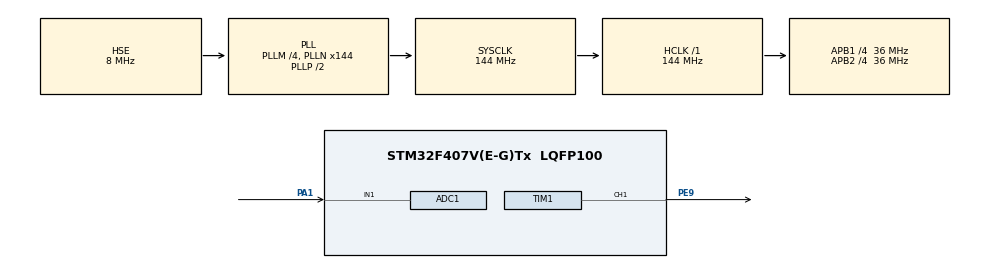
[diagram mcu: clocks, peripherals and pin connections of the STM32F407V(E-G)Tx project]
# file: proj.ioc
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ADC1.Channel-0\#ChannelRegularConversion=ADC_CHANNEL_1
ADC1.ClockPrescaler=ADC_CLOCK_SYNC_PCLK_DIV8
ADC1.ContinuousConvMode=ENABLE
ADC1.DMAContinuousRequests=ENABLE
ADC1.EOCSelection=ADC_EOC_SEQ_CONV
ADC1.NbrOfConversion=1
ADC1.NbrOfConversionFlag=1
ADC1.Rank-0\#ChannelRegularConversion=1
ADC1.SamplingTime-0\#ChannelRegularConversion=ADC_SAMPLETIME_112CYCLES
ADC1.master=1
Dma.ADC1.1.Direction=DMA_PERIPH_TO_MEMORY
Dma.ADC1.1.FIFOMode=DMA_FIFOMODE_DISABLE
Dma.ADC1.1.Instance=DMA2_Stream0
Dma.ADC1.1.MemDataAlignment=DMA_MDATAALIGN_HALFWORD
Dma.ADC1.1.MemInc=DMA_MINC_ENABLE
Dma.ADC1.1.Mode=DMA_NORMAL
Dma.ADC1.1.PeriphDataAlignment=DMA_PDATAALIGN_HALFWORD
Dma.ADC1.1.PeriphInc=DMA_PINC_DISABLE
Dma.ADC1.1.Priority=DMA_PRIORITY_LOW
Dma.Request0=TIM1_CH1
Dma.Request1=ADC1
Dma.TIM1_CH1.0.Direction=DMA_MEMORY_TO_PERIPH
Dma.TIM1_CH1.0.FIFOMode=DMA_FIFOMODE_DISABLE
Dma.TIM1_CH1.0.Instance=DMA2_Stream1
Dma.TIM1_CH1.0.MemDataAlignment=DMA_MDATAALIGN_HALFWORD
Dma.TIM1_CH1.0.MemInc=DMA_MINC_ENABLE
Dma.TIM1_CH1.0.Mode=DMA_NORMAL
Dma.TIM1_CH1.0.PeriphDataAlignment=DMA_PDATAALIGN_HALFWORD
Dma.TIM1_CH1.0.PeriphInc=DMA_PINC_DISABLE
Dma.TIM1_CH1.0.Priority=DMA_PRIORITY_LOW
Mcu.Family=STM32F4
Mcu.Name=STM32F407V(E-G)Tx
Mcu.Package=LQFP100
NVIC.DMA2_Stream0_IRQn=true\:0\:0\:false\:false\:true\:false\:true
NVIC.DMA2_Stream1_IRQn=true\:0\:0\:false\:false\:true\:false\:true
NVIC.PriorityGroup=NVIC_PRIORITYGROUP_4
PA1.Signal=ADCx_IN1
PE9.Signal=S_TIM1_CH1
PH0-OSC_IN.Mode=HSE-External-Oscillator
PH0-OSC_IN.Signal=RCC_OSC_IN
PH1-OSC_OUT.Mode=HSE-External-Oscillator
PH1-OSC_OUT.Signal=RCC_OSC_OUT
ProjectManager.HeapSize=0x200
ProjectManager.StackSize=0x400
ProjectManager.TargetToolchain=STM32CubeIDE
RCC.48MHZClocksFreq_Value=72000000
RCC.AHBFreq_Value=144000000
RCC.APB1CLKDivider=RCC_HCLK_DIV4
RCC.APB1Freq_Value=36000000
RCC.APB1TimFreq_Value=72000000
RCC.APB2CLKDivider=RCC_HCLK_DIV4
RCC.APB2Freq_Value=36000000
RCC.APB2TimFreq_Value=72000000
RCC.CortexFreq_Value=144000000
RCC.HCLKFreq_Value=144000000
RCC.HSE_VALUE=8000000
RCC.HSI_VALUE=16000000
RCC.LSE_VALUE=0
RCC.PLLM=4
RCC.PLLN=144
RCC.PLLSourceVirtual=RCC_PLLSOURCE_HSE
RCC.SYSCLKFreq_VALUE=144000000
RCC.SYSCLKSource=RCC_SYSCLKSOURCE_PLLCLK
RCC.VCOOutputFreq_Value=288000000
SH.ADCx_IN1.0=ADC1_IN1,IN1
SH.S_TIM1_CH1.0=TIM1_CH1,PWM Generation1 CH1
TIM1.Channel-PWM\ Generation1\ CH1=TIM_CHANNEL_1
TIM1.Period=90-1
VP_TIM1_VS_ClockSourceINT.Mode=Internal
board=custom

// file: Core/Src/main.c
/* USER CODE BEGIN Header */
/**
  ******************************************************************************
  * @file           : main.c
  * @brief          : Main program body
  ******************************************************************************
  * @attention
  *
  * <h2><center>&copy; Copyright (c) 2021 STMicroelectronics.
  * All rights reserved.</center></h2>
  *
  * This software component is licensed by ST under BSD 3-Clause license,
  * the "License"; You may not use this file except in compliance with the
  * License. You may obtain a copy of the License at:
  *                        opensource.org/licenses/BSD-3-Clause
  *
  ******************************************************************************
  */
/* USER CODE END Header */
#include "main.h"

ADC_HandleTypeDef hadc1;
DMA_HandleTypeDef hdma_adc1;

TIM_HandleTypeDef htim1;
DMA_HandleTypeDef hdma_tim1_ch1;

/* USER CODE BEGIN PV */
uint8_t flag_adc_dma = 0;
/* USER CODE END PV */

void SystemClock_Config(void);
static void MX_GPIO_Init(void);
static void MX_DMA_Init(void);
static void MX_TIM1_Init(void);
static void MX_ADC1_Init(void);

/* USER CODE BEGIN 0 */
#define MAX_LED 64 // max LEDs that we have in a cascade

uint8_t LED_Data[MAX_LED][4];  // matrix of 4 columns, number of rows = number of LEDs we have

int datasentflag=0;  // to make sure that the dma does not send another data while the first data is still transmitted

void HAL_TIM_PWM_PulseFinishedCallback(TIM_HandleTypeDef *htim)  // this callback is called when data transmission is finished
{
	HAL_TIM_PWM_Stop_DMA(&htim1, TIM_CHANNEL_1);  // stop dma, when the transmission is finished
	datasentflag = 1;
}

void Set_LED (int LEDnum, int Red, int Green, int Blue)
{
	LED_Data[LEDnum][0] = LEDnum;
	LED_Data[LEDnum][1] = Green;  // store green first as ws2821b requires this order (g,r,b)
	LED_Data[LEDnum][2] = Red;
	LED_Data[LEDnum][3] = Blue;
}

uint16_t pwmData[(24*MAX_LED)+50]; // store 24 bits for each led + 50 values for reset code

void WS2812_Send (void)
{
	uint32_t indx=0;
	uint32_t color;  //32 bit variable to store 24 bits of color

	for (int i= 0; i<MAX_LED; i++)  // iterate through all of the LEDs
	{

		color = ((LED_Data[i][1]<<16) | (LED_Data[i][2]<<8) | (LED_Data[i][3])); // green red blue

		for (int i=23; i>=0; i--) // iterate through the 24 bits which specify the color
		{
			if (color&(1<<i))
			{
				pwmData[indx] = 57; // if the bit is 1, the duty cycle is 64%
			}

			else pwmData[indx] = 28;  // if the bit is 0, the duty cycle is 32%

			indx++;
		}

	}

	for (int i=0; i<50; i++)  // store values to keep the pulse low for 50+ us, reset code
	{
		pwmData[indx] = 0;
		indx++;
	}
	HAL_TIM_PWM_Start_DMA(&htim1, TIM_CHANNEL_1, (uint32_t *)pwmData, indx);  // send the data to the dma
	while (!datasentflag){};  // this flag will be set when the data transmission is finished, dma is stopped and now we can send another data
	datasentflag = 0;
}
/* USER CODE END 0 */

int main(void)
{

  /* MCU Configuration--------------------------------------------------------*/

  /* Reset of all peripherals, Initializes the Flash interface and the Systick. */
  HAL_Init();

  /* Configure the system clock */
  SystemClock_Config();

  /* Initialize all configured peripherals */
  MX_GPIO_Init();
  MX_DMA_Init();
  MX_TIM1_Init();
  MX_ADC1_Init();
  /* USER CODE BEGIN 2 */

  uint16_t ADCBuffer[1024];

  HAL_ADC_Start_DMA(&hadc1,(uint16_t *)&ADCBuffer, (1024 * 2));
  if(flag_adc_dma == 1){
	  HAL_ADC_Stop_DMA(&hadc1);
	  flag_adc_dma = 0;
  }

  int lst[64];
    for(int i = 0; i < 64; i++){
        lst[i] = 0;
    }
    //put the first one to the end and increase by a certain number
    int v[8] = {2, 5, 4, 8, 3, 5, 8, 2};
    for(int k=0; k<8; k++){
        int lst_position = k + 64;
        int meaning = v[k];
        int temp = 0;
        while(temp < meaning){
            temp += 1;
            lst_position -= 7;
            lst[lst_position] = 1;
            lst_position--;
        }
    }

        void WS_Reset(void){
        	for (int i=0; i < 64; i++){
            Set_LED(i, 0, 0, 0);
          }
        	WS2812_Send();
        }

        void WS_Set(int matrix[]){
            for (int i=0; i < 64; i++){
              if (matrix[i]==1){
                Set_LED(i, 67, 4, 4);
              }
              else {
                Set_LED(i, 0, 0, 0);
              }
            }
            WS2812_Send();
        }
  /* USER CODE END 2 */

  /* Infinite loop */
  /* USER CODE BEGIN WHILE */
  while (1)
  {
	  WS_Set(lst);
	  HAL_Delay(200);

	  //	 		  	  WS_Reset();
	  //	 		  	  HAL_Delay(200);
    /* USER CODE END WHILE */

  }
}

void SystemClock_Config(void)
{
  RCC_OscInitTypeDef RCC_OscInitStruct = {0};
  RCC_ClkInitTypeDef RCC_ClkInitStruct = {0};

  /** Configure the main internal regulator output voltage
  */
  __HAL_RCC_PWR_CLK_ENABLE();
  __HAL_PWR_VOLTAGESCALING_CONFIG(PWR_REGULATOR_VOLTAGE_SCALE1);
  /** Initializes the RCC Oscillators according to the specified parameters
  * in the RCC_OscInitTypeDef structure.
  */
  RCC_OscInitStruct.OscillatorType = RCC_OSCILLATORTYPE_HSE;
  RCC_OscInitStruct.HSEState = RCC_HSE_ON;
  RCC_OscInitStruct.PLL.PLLState = RCC_PLL_ON;
  RCC_OscInitStruct.PLL.PLLSource = RCC_PLLSOURCE_HSE;
  RCC_OscInitStruct.PLL.PLLM = 4;
  RCC_OscInitStruct.PLL.PLLN = 144;
  RCC_OscInitStruct.PLL.PLLP = RCC_PLLP_DIV2;
  RCC_OscInitStruct.PLL.PLLQ = 4;
  if (HAL_RCC_OscConfig(&RCC_OscInitStruct) != HAL_OK)
  {
    Error_Handler();
  }
  /** Initializes the CPU, AHB and APB buses clocks
  */
  RCC_ClkInitStruct.ClockType = RCC_CLOCKTYPE_HCLK|RCC_CLOCKTYPE_SYSCLK
                              |RCC_CLOCKTYPE_PCLK1|RCC_CLOCKTYPE_PCLK2;
  RCC_ClkInitStruct.SYSCLKSource = RCC_SYSCLKSOURCE_PLLCLK;
  RCC_ClkInitStruct.AHBCLKDivider = RCC_SYSCLK_DIV1;
  RCC_ClkInitStruct.APB1CLKDivider = RCC_HCLK_DIV4;
  RCC_ClkInitStruct.APB2CLKDivider = RCC_HCLK_DIV4;

  if (HAL_RCC_ClockConfig(&RCC_ClkInitStruct, FLASH_LATENCY_4) != HAL_OK)
  {
    Error_Handler();
  }
}

static void MX_ADC1_Init(void)
{

  ADC_ChannelConfTypeDef sConfig = {0};

  /** Configure the global features of the ADC (Clock, Resolution, Data Alignment and number of conversion)
  */
  hadc1.Instance = ADC1;
  hadc1.Init.ClockPrescaler = ADC_CLOCK_SYNC_PCLK_DIV8;
  hadc1.Init.Resolution = ADC_RESOLUTION_12B;
  hadc1.Init.ScanConvMode = DISABLE;
  hadc1.Init.ContinuousConvMode = ENABLE;
  hadc1.Init.DiscontinuousConvMode = DISABLE;
  hadc1.Init.ExternalTrigConvEdge = ADC_EXTERNALTRIGCONVEDGE_NONE;
  hadc1.Init.ExternalTrigConv = ADC_SOFTWARE_START;
  hadc1.Init.DataAlign = ADC_DATAALIGN_RIGHT;
  hadc1.Init.NbrOfConversion = 1;
  hadc1.Init.DMAContinuousRequests = ENABLE;
  hadc1.Init.EOCSelection = ADC_EOC_SEQ_CONV;
  if (HAL_ADC_Init(&hadc1) != HAL_OK)
  {
    Error_Handler();
  }
  /** Configure for the selected ADC regular channel its corresponding rank in the sequencer and its sample time.
  */
  sConfig.Channel = ADC_CHANNEL_1;
  sConfig.Rank = 1;
  sConfig.SamplingTime = ADC_SAMPLETIME_112CYCLES;
  if (HAL_ADC_ConfigChannel(&hadc1, &sConfig) != HAL_OK)
  {
    Error_Handler();
  }

}

static void MX_TIM1_Init(void)
{

  TIM_ClockConfigTypeDef sClockSourceConfig = {0};
  TIM_MasterConfigTypeDef sMasterConfig = {0};
  TIM_OC_InitTypeDef sConfigOC = {0};
  TIM_BreakDeadTimeConfigTypeDef sBreakDeadTimeConfig = {0};

  htim1.Instance = TIM1;
  htim1.Init.Prescaler = 0;
  htim1.Init.CounterMode = TIM_COUNTERMODE_UP;
  htim1.Init.Period = 90-1;
  htim1.Init.ClockDivision = TIM_CLOCKDIVISION_DIV1;
  htim1.Init.RepetitionCounter = 0;
  htim1.Init.AutoReloadPreload = TIM_AUTORELOAD_PRELOAD_DISABLE;
  if (HAL_TIM_Base_Init(&htim1) != HAL_OK)
  {
    Error_Handler();
  }
  sClockSourceConfig.ClockSource = TIM_CLOCKSOURCE_INTERNAL;
  if (HAL_TIM_ConfigClockSource(&htim1, &sClockSourceConfig) != HAL_OK)
  {
    Error_Handler();
  }
  if (HAL_TIM_PWM_Init(&htim1) != HAL_OK)
  {
    Error_Handler();
  }
  sMasterConfig.MasterOutputTrigger = TIM_TRGO_RESET;
  sMasterConfig.MasterSlaveMode = TIM_MASTERSLAVEMODE_DISABLE;
  if (HAL_TIMEx_MasterConfigSynchronization(&htim1, &sMasterConfig) != HAL_OK)
  {
    Error_Handler();
  }
  sConfigOC.OCMode = TIM_OCMODE_PWM1;
  sConfigOC.Pulse = 0;
  sConfigOC.OCPolarity = TIM_OCPOLARITY_HIGH;
  sConfigOC.OCNPolarity = TIM_OCNPOLARITY_HIGH;
  sConfigOC.OCFastMode = TIM_OCFAST_DISABLE;
  sConfigOC.OCIdleState = TIM_OCIDLESTATE_RESET;
  sConfigOC.OCNIdleState = TIM_OCNIDLESTATE_RESET;
  if (HAL_TIM_PWM_ConfigChannel(&htim1, &sConfigOC, TIM_CHANNEL_1) != HAL_OK)
  {
    Error_Handler();
  }
  sBreakDeadTimeConfig.OffStateRunMode = TIM_OSSR_DISABLE;
  sBreakDeadTimeConfig.OffStateIDLEMode = TIM_OSSI_DISABLE;
  sBreakDeadTimeConfig.LockLevel = TIM_LOCKLEVEL_OFF;
  sBreakDeadTimeConfig.DeadTime = 0;
  sBreakDeadTimeConfig.BreakState = TIM_BREAK_DISABLE;
  sBreakDeadTimeConfig.BreakPolarity = TIM_BREAKPOLARITY_HIGH;
  sBreakDeadTimeConfig.AutomaticOutput = TIM_AUTOMATICOUTPUT_DISABLE;
  if (HAL_TIMEx_ConfigBreakDeadTime(&htim1, &sBreakDeadTimeConfig) != HAL_OK)
  {
    Error_Handler();
  }
  HAL_TIM_MspPostInit(&htim1);

}

static void MX_DMA_Init(void)
{

  /* DMA controller clock enable */
  __HAL_RCC_DMA2_CLK_ENABLE();

  /* DMA interrupt init */
  /* DMA2_Stream0_IRQn interrupt configuration */
  HAL_NVIC_SetPriority(DMA2_Stream0_IRQn, 0, 0);
  HAL_NVIC_EnableIRQ(DMA2_Stream0_IRQn);
  /* DMA2_Stream1_IRQn interrupt configuration */
  HAL_NVIC_SetPriority(DMA2_Stream1_IRQn, 0, 0);
  HAL_NVIC_EnableIRQ(DMA2_Stream1_IRQn);

}

static void MX_GPIO_Init(void)
{

  /* GPIO Ports Clock Enable */
  __HAL_RCC_GPIOH_CLK_ENABLE();
  __HAL_RCC_GPIOA_CLK_ENABLE();
  __HAL_RCC_GPIOE_CLK_ENABLE();

}

void Error_Handler(void)
{
  __disable_irq();
  while (1)
  {
  }
}

/************************ (C) COPYRIGHT STMicroelectronics *****END OF FILE****/
